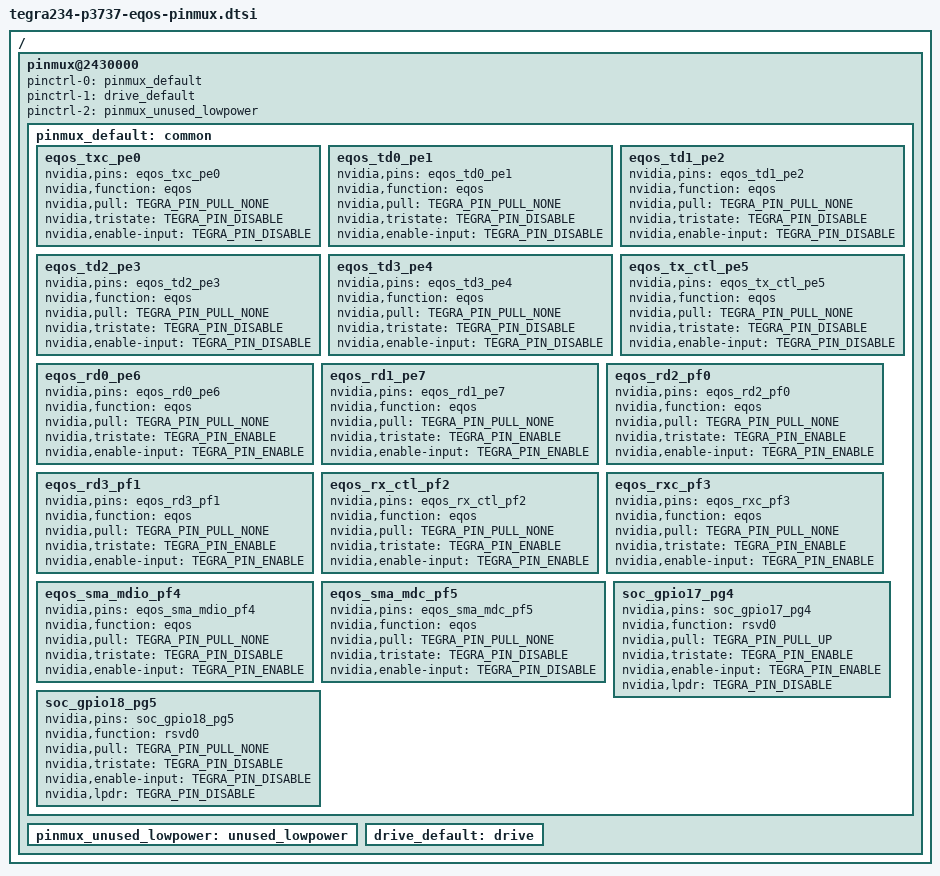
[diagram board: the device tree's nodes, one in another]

/ {
	pinmux@2430000 {
		pinctrl-names = "default", "drive", "unused";
		pinctrl-0 = <&pinmux_default>;
		pinctrl-1 = <&drive_default>;
		pinctrl-2 = <&pinmux_unused_lowpower>;
		pinmux_default: common {
			eqos_txc_pe0 {
				nvidia,pins = "eqos_txc_pe0";
				nvidia,function = "eqos";
				nvidia,pull = <TEGRA_PIN_PULL_NONE>;
				nvidia,tristate = <TEGRA_PIN_DISABLE>;
				nvidia,enable-input = <TEGRA_PIN_DISABLE>;
			};

			eqos_td0_pe1 {
				nvidia,pins = "eqos_td0_pe1";
				nvidia,function = "eqos";
				nvidia,pull = <TEGRA_PIN_PULL_NONE>;
				nvidia,tristate = <TEGRA_PIN_DISABLE>;
				nvidia,enable-input = <TEGRA_PIN_DISABLE>;
			};

			eqos_td1_pe2 {
				nvidia,pins = "eqos_td1_pe2";
				nvidia,function = "eqos";
				nvidia,pull = <TEGRA_PIN_PULL_NONE>;
				nvidia,tristate = <TEGRA_PIN_DISABLE>;
				nvidia,enable-input = <TEGRA_PIN_DISABLE>;
			};

			eqos_td2_pe3 {
				nvidia,pins = "eqos_td2_pe3";
				nvidia,function = "eqos";
				nvidia,pull = <TEGRA_PIN_PULL_NONE>;
				nvidia,tristate = <TEGRA_PIN_DISABLE>;
				nvidia,enable-input = <TEGRA_PIN_DISABLE>;
			};

			eqos_td3_pe4 {
				nvidia,pins = "eqos_td3_pe4";
				nvidia,function = "eqos";
				nvidia,pull = <TEGRA_PIN_PULL_NONE>;
				nvidia,tristate = <TEGRA_PIN_DISABLE>;
				nvidia,enable-input = <TEGRA_PIN_DISABLE>;
			};

			eqos_tx_ctl_pe5 {
				nvidia,pins = "eqos_tx_ctl_pe5";
				nvidia,function = "eqos";
				nvidia,pull = <TEGRA_PIN_PULL_NONE>;
				nvidia,tristate = <TEGRA_PIN_DISABLE>;
				nvidia,enable-input = <TEGRA_PIN_DISABLE>;
			};

			eqos_rd0_pe6 {
				nvidia,pins = "eqos_rd0_pe6";
				nvidia,function = "eqos";
				nvidia,pull = <TEGRA_PIN_PULL_NONE>;
				nvidia,tristate = <TEGRA_PIN_ENABLE>;
				nvidia,enable-input = <TEGRA_PIN_ENABLE>;
			};

			eqos_rd1_pe7 {
				nvidia,pins = "eqos_rd1_pe7";
				nvidia,function = "eqos";
				nvidia,pull = <TEGRA_PIN_PULL_NONE>;
				nvidia,tristate = <TEGRA_PIN_ENABLE>;
				nvidia,enable-input = <TEGRA_PIN_ENABLE>;
			};
			eqos_rd2_pf0 {
				nvidia,pins = "eqos_rd2_pf0";
				nvidia,function = "eqos";
				nvidia,pull = <TEGRA_PIN_PULL_NONE>;
				nvidia,tristate = <TEGRA_PIN_ENABLE>;
				nvidia,enable-input = <TEGRA_PIN_ENABLE>;
			};

			eqos_rd3_pf1 {
				nvidia,pins = "eqos_rd3_pf1";
				nvidia,function = "eqos";
				nvidia,pull = <TEGRA_PIN_PULL_NONE>;
				nvidia,tristate = <TEGRA_PIN_ENABLE>;
				nvidia,enable-input = <TEGRA_PIN_ENABLE>;
			};

			eqos_rx_ctl_pf2 {
				nvidia,pins = "eqos_rx_ctl_pf2";
				nvidia,function = "eqos";
				nvidia,pull = <TEGRA_PIN_PULL_NONE>;
				nvidia,tristate = <TEGRA_PIN_ENABLE>;
				nvidia,enable-input = <TEGRA_PIN_ENABLE>;
			};

			eqos_rxc_pf3 {
				nvidia,pins = "eqos_rxc_pf3";
				nvidia,function = "eqos";
				nvidia,pull = <TEGRA_PIN_PULL_NONE>;
				nvidia,tristate = <TEGRA_PIN_ENABLE>;
				nvidia,enable-input = <TEGRA_PIN_ENABLE>;
			};

			eqos_sma_mdio_pf4 {
				nvidia,pins = "eqos_sma_mdio_pf4";
				nvidia,function = "eqos";
				nvidia,pull = <TEGRA_PIN_PULL_NONE>;
				nvidia,tristate = <TEGRA_PIN_DISABLE>;
				nvidia,enable-input = <TEGRA_PIN_ENABLE>;
			};

			eqos_sma_mdc_pf5 {
				nvidia,pins = "eqos_sma_mdc_pf5";
				nvidia,function = "eqos";
				nvidia,pull = <TEGRA_PIN_PULL_NONE>;
				nvidia,tristate = <TEGRA_PIN_DISABLE>;
				nvidia,enable-input = <TEGRA_PIN_DISABLE>;
			};
			soc_gpio17_pg4 {
				nvidia,pins = "soc_gpio17_pg4";
				nvidia,function = "rsvd0";
				nvidia,pull = <TEGRA_PIN_PULL_UP>;
				nvidia,tristate = <TEGRA_PIN_ENABLE>;
				nvidia,enable-input = <TEGRA_PIN_ENABLE>;
				nvidia,lpdr = <TEGRA_PIN_DISABLE>;
			};

			soc_gpio18_pg5 {
				nvidia,pins = "soc_gpio18_pg5";
				nvidia,function = "rsvd0";
				nvidia,pull = <TEGRA_PIN_PULL_NONE>;
				nvidia,tristate = <TEGRA_PIN_DISABLE>;
				nvidia,enable-input = <TEGRA_PIN_DISABLE>;
				nvidia,lpdr = <TEGRA_PIN_DISABLE>;
			};
		};
		pinmux_unused_lowpower: unused_lowpower {
		};
		drive_default: drive {
		};
	};

};

